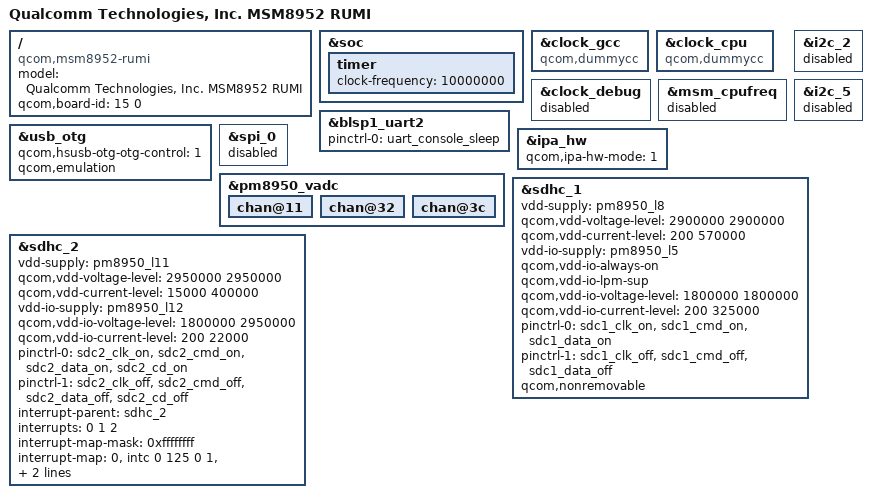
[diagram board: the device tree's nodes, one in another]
/*
 * Copyright (c) 2014-2015, The Linux Foundation. All rights reserved.
 *
 * This program is free software; you can redistribute it and/or modify
 * it under the terms of the GNU General Public License version 2 and
 * only version 2 as published by the Free Software Foundation.
 *
 * This program is distributed in the hope that it will be useful,
 * but WITHOUT ANY WARRANTY; without even the implied warranty of
 * MERCHANTABILITY or FITNESS FOR A PARTICULAR PURPOSE.  See the
 * GNU General Public License for more details.
 */

/dts-v1/;

#include "msm8952.dtsi"

/ {
	model = "Qualcomm Technologies, Inc. MSM8952 RUMI";
	compatible = "qcom,msm8952-rumi", "qcom,msm8952", "qcom,rumi";
	qcom,board-id= <15 0>;
};

&soc {
	timer {
		clock-frequency = <10000000>;
	};
};

&clock_gcc {
	compatible = "qcom,dummycc";
	#clock-cells = <1>;
};

&clock_cpu {
	compatible = "qcom,dummycc";
	#clock-cells = <1>;
};

&clock_debug {
	status = "disabled";
};

&msm_cpufreq {
	status = "disabled";
};

&blsp1_uart2 {
	status = "ok";
	pinctrl-names = "default";
	pinctrl-0 = <&uart_console_sleep>;
};

&usb_otg {
	qcom,hsusb-otg-otg-control = <1>;
	qcom,emulation;
};

&i2c_2 {
	status = "disabled";
};

&i2c_5 {
	status = "disabled";
};

&spi_0 {
	status = "disabled";
};

&ipa_hw {
	qcom,ipa-hw-mode = <1>; /* IPA hw type = Virtual */
};

&pm8950_vadc {
	chan@11 {
		/delete-property/ qcom,vadc-thermal-node;
	};
	chan@32 {
		/delete-property/ qcom,vadc-thermal-node;
	};
	chan@3c {
		/delete-property/ qcom,vadc-thermal-node;
	};
};

&sdhc_1 {
	vdd-supply = <&pm8950_l8>;
	qcom,vdd-voltage-level = <2900000 2900000>;
	qcom,vdd-current-level = <200 570000>;

	vdd-io-supply = <&pm8950_l5>;
	qcom,vdd-io-always-on;
	qcom,vdd-io-lpm-sup;
	qcom,vdd-io-voltage-level = <1800000 1800000>;
	qcom,vdd-io-current-level = <200 325000>;

	pinctrl-names = "active", "sleep";
	pinctrl-0 = <&sdc1_clk_on &sdc1_cmd_on &sdc1_data_on>;
	pinctrl-1 = <&sdc1_clk_off &sdc1_cmd_off &sdc1_data_off>;

	qcom,nonremovable;
	status = "ok";
};

&sdhc_2 {
	vdd-supply = <&pm8950_l11>;
	qcom,vdd-voltage-level = <2950000 2950000>;
	qcom,vdd-current-level = <15000 400000>;

	vdd-io-supply = <&pm8950_l12>;
	qcom,vdd-io-voltage-level = <1800000 2950000>;
	qcom,vdd-io-current-level = <200 22000>;

	pinctrl-names = "active", "sleep";
	pinctrl-0 = <&sdc2_clk_on &sdc2_cmd_on &sdc2_data_on &sdc2_cd_on>;
	pinctrl-1 = <&sdc2_clk_off &sdc2_cmd_off &sdc2_data_off &sdc2_cd_off>;

	#address-cells = <0>;
	interrupt-parent = <&sdhc_2>;
	interrupts = <0 1 2>;
	#interrupt-cells = <1>;
	interrupt-map-mask = <0xffffffff>;
	interrupt-map = <0 &intc 0 125 0
			1 &intc 0 221 0
			2 &msm_gpio 67 0>;
	interrupt-names = "hc_irq", "pwr_irq", "status_irq";
	cd-gpios = <&msm_gpio 67 0x1>;
	status = "ok";
};
